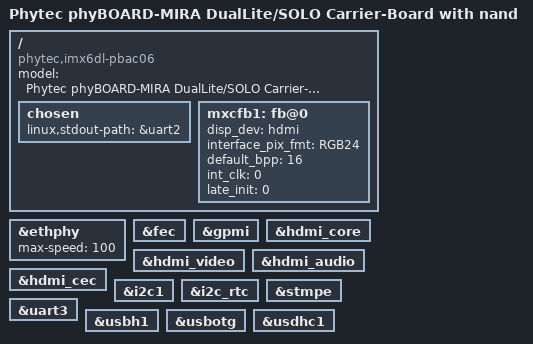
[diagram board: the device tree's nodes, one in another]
/*
 * Copyright (C) 2015 PHYTEC Messtechnik
 * Author: Christian Hemp <c.hemp@phytec.de>
 *
 * The code contained herein is licensed under the GNU General Public
 * License. You may obtain a copy of the GNU General Public License
 * Version 2 or later at the following locations:
 *
 * http://www.opensource.org/licenses/gpl-license.html
 * http://www.gnu.org/copyleft/gpl.html
 */

/dts-v1/;
#include "imx6dl.dtsi"
#include "imx6qdl-phytec-phycore-som.dtsi"
#include "imx6qdl-phytec-mira.dtsi"
#include "imx6qdl-phytec-mira-peb-eval-01.dtsi"

/ {
	model = "Phytec phyBOARD-MIRA DualLite/SOLO Carrier-Board with nand";
	compatible = "phytec,imx6dl-pbac06", "phytec,imx6qdl-pcm058", "fsl,imx6dl";

	chosen {
		linux,stdout-path = &uart2;
	};

	mxcfb1: fb@0 {
		disp_dev = "hdmi";
		interface_pix_fmt = "RGB24";
		default_bpp = <16>;
		int_clk = <0>;
		late_init = <0>;
		status = "okay";
	};
};

&ethphy {
	max-speed = <100>;
};

&fec {
	status = "okay";
};

&gpmi {
	status = "okay";
};

&hdmi_core {
	status = "okay";
};

&hdmi_video {
	status = "okay";
};

&hdmi_audio {
	status = "okay";
};

&hdmi_cec {
	status = "okay";
};

&i2c1 {
	status = "okay";
};

&i2c_rtc {
	status = "okay";
};

&stmpe {
	status = "okay";
};

&uart3 {
	status = "okay";
};

&usbh1 {
	status = "okay";
};

&usbotg {
	status = "okay";
};

&usdhc1 {
	status = "okay";
};
